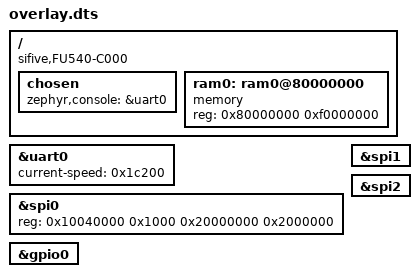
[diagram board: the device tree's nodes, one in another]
/ {
	compatible = "sifive,FU540-C000", "fu540-dev", "sifive-dev";
	chosen {
		zephyr,console = &uart0;
	};
	ram0: ram0@80000000 {
		compatible = "memory";
		reg = <0x80000000 0xf0000000>;
		reg-names = "mem";
	};
};
&uart0{
	status = "okay";
	current-speed = < 0x1c200 >;
};
&spi0{
	reg = < 0x10040000 0x1000 0x20000000 0x2000000 >;
};
&spi1{
	status = "okay";
};
&spi2{
	status = "okay";
};
&gpio0{
	status = "okay";
};
